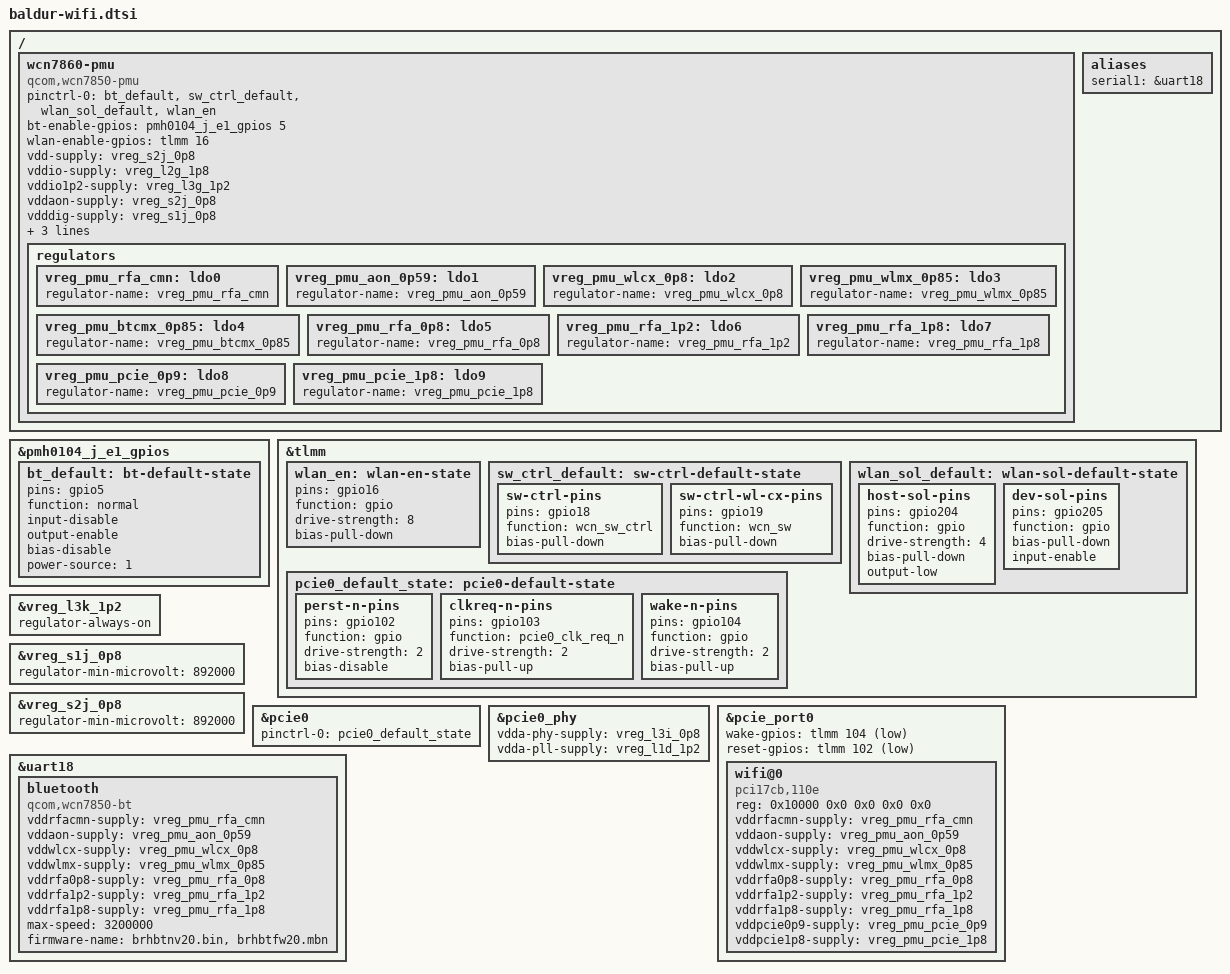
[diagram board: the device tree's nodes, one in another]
// SPDX-License-Identifier: BSD-3-Clause
/*
 * TB323FU ("baldur"): Wi-Fi, WCN7860 "peach" (17cb:110e) on PCIe0, ath12k.
 *
 * Pins as on the OnePlus 15 port and kaanapali-mtp.dts: wlan-en gpio16,
 * sw-ctrl gpio18, PERST gpio102, CLKREQ gpio103, WAKE gpio104. The rails are
 * this device's own, from its vendor cnss-peach node: AON 0.9 V comes from
 * S2J here, not from S7G as on the MTP.
 *
 * BT_EN is described so that the sequencer drives it low before it powers
 * WLAN, as the vendor cnss does: a PMIC GPIO keeps its level across a warm
 * reboot. Needs pmh0104-kaanapali.dtsi.
 */

&pmh0104_j_e1_gpios {
	bt_default: bt-default-state {
		pins = "gpio5";
		function = "normal";
		input-disable;
		output-enable;
		bias-disable;
		power-source = <1>;
	};
};

&tlmm {
	wlan_en: wlan-en-state {
		pins = "gpio16";
		function = "gpio";
		drive-strength = <8>;
		bias-pull-down;
	};

	/* vendor cnss_wlan_sw_ctrl / cnss_wlan_sw_ctrl_wl_cx */
	sw_ctrl_default: sw-ctrl-default-state {
		sw-ctrl-pins {
			pins = "gpio18";
			function = "wcn_sw_ctrl";
			bias-pull-down;
		};

		sw-ctrl-wl-cx-pins {
			pins = "gpio19";
			function = "wcn_sw";
			bias-pull-down;
		};
	};

	/*
	 * Sign-of-life lines (vendor wlan-host-sol-gpio 204, wlan-dev-sol-gpio
	 * 205): eGPIOs that another subsystem owns until something selects
	 * function "gpio". Host-SOL goes low before the chip is powered.
	 */
	wlan_sol_default: wlan-sol-default-state {
		host-sol-pins {
			pins = "gpio204";
			function = "gpio";
			drive-strength = <4>;
			bias-pull-down;
			output-low;
		};

		dev-sol-pins {
			pins = "gpio205";
			function = "gpio";
			bias-pull-down;
			input-enable;
		};
	};

	pcie0_default_state: pcie0-default-state {
		perst-n-pins {
			pins = "gpio102";
			function = "gpio";
			drive-strength = <2>;
			bias-disable;
		};

		clkreq-n-pins {
			pins = "gpio103";
			function = "pcie0_clk_req_n";
			drive-strength = <2>;
			bias-pull-up;
		};

		wake-n-pins {
			pins = "gpio104";
			function = "gpio";
			drive-strength = <2>;
			bias-pull-up;
		};
	};
};

/ {
	wcn7860-pmu {
		/* no WCN7860 binding; the WCN7850 sequencer is what the OnePlus port uses */
		compatible = "qcom,wcn7850-pmu";

		pinctrl-0 = <&bt_default>, <&sw_ctrl_default>, <&wlan_sol_default>, <&wlan_en>;
		pinctrl-names = "default";

		bt-enable-gpios = <&pmh0104_j_e1_gpios 5 GPIO_ACTIVE_HIGH>;
		wlan-enable-gpios = <&tlmm 16 GPIO_ACTIVE_HIGH>;

		vdd-supply = <&vreg_s2j_0p8>;
		vddio-supply = <&vreg_l2g_1p8>;
		vddio1p2-supply = <&vreg_l3g_1p2>;
		vddaon-supply = <&vreg_s2j_0p8>;
		vdddig-supply = <&vreg_s1j_0p8>;
		vddrfa1p2-supply = <&vreg_s7f_1p2>;
		vddrfa1p8-supply = <&vreg_s8f_1p8>;

		clocks = <&rpmhcc RPMH_RF_CLK1>;

		regulators {
			vreg_pmu_rfa_cmn: ldo0 {
				regulator-name = "vreg_pmu_rfa_cmn";
			};

			vreg_pmu_aon_0p59: ldo1 {
				regulator-name = "vreg_pmu_aon_0p59";
			};

			vreg_pmu_wlcx_0p8: ldo2 {
				regulator-name = "vreg_pmu_wlcx_0p8";
			};

			vreg_pmu_wlmx_0p85: ldo3 {
				regulator-name = "vreg_pmu_wlmx_0p85";
			};

			vreg_pmu_btcmx_0p85: ldo4 {
				regulator-name = "vreg_pmu_btcmx_0p85";
			};

			vreg_pmu_rfa_0p8: ldo5 {
				regulator-name = "vreg_pmu_rfa_0p8";
			};

			vreg_pmu_rfa_1p2: ldo6 {
				regulator-name = "vreg_pmu_rfa_1p2";
			};

			vreg_pmu_rfa_1p8: ldo7 {
				regulator-name = "vreg_pmu_rfa_1p8";
			};

			vreg_pmu_pcie_0p9: ldo8 {
				regulator-name = "vreg_pmu_pcie_0p9";
			};

			vreg_pmu_pcie_1p8: ldo9 {
				regulator-name = "vreg_pmu_pcie_1p8";
			};
		};
	};
};

&vreg_l3k_1p2 {
	regulator-always-on;
};

/*
 * WLCX/WLMX at the vendor cnss votes: the regulator core parks an unset rail
 * at its minimum (0.4/0.5 V), and nothing raises them through the PDC here.
 */
&vreg_s1j_0p8 {
	regulator-min-microvolt = <892000>;
};

&vreg_s2j_0p8 {
	regulator-min-microvolt = <892000>;
};

&pcie0 {
	pinctrl-0 = <&pcie0_default_state>;
	pinctrl-names = "default";

	status = "okay";
};

&pcie0_phy {
	vdda-phy-supply = <&vreg_l3i_0p8>;
	vdda-pll-supply = <&vreg_l1d_1p2>;

	status = "okay";
};

&pcie_port0 {
	wake-gpios = <&tlmm 104 GPIO_ACTIVE_LOW>;
	reset-gpios = <&tlmm 102 GPIO_ACTIVE_LOW>;

	wifi@0 {
		compatible = "pci17cb,110e";
		reg = <0x10000 0x0 0x0 0x0 0x0>;

		vddrfacmn-supply = <&vreg_pmu_rfa_cmn>;
		vddaon-supply = <&vreg_pmu_aon_0p59>;
		vddwlcx-supply = <&vreg_pmu_wlcx_0p8>;
		vddwlmx-supply = <&vreg_pmu_wlmx_0p85>;
		vddrfa0p8-supply = <&vreg_pmu_rfa_0p8>;
		vddrfa1p2-supply = <&vreg_pmu_rfa_1p2>;
		vddrfa1p8-supply = <&vreg_pmu_rfa_1p8>;
		vddpcie0p9-supply = <&vreg_pmu_pcie_0p9>;
		vddpcie1p8-supply = <&vreg_pmu_pcie_1p8>;
	};
};

/*
 * Bluetooth, the same chip over the 4-wire HS-UART (vendor
 * qupv3_se18_4uart @ 0x1994000 = uart18), as the OnePlus 15 port wires it.
 */
/ {
	aliases {
		/* the geni UART driver wants a line number */
		serial1 = &uart18;
	};
};

&uart18 {
	status = "okay";

	bluetooth {
		compatible = "qcom,wcn7850-bt";

		vddrfacmn-supply = <&vreg_pmu_rfa_cmn>;
		vddaon-supply = <&vreg_pmu_aon_0p59>;
		vddwlcx-supply = <&vreg_pmu_wlcx_0p8>;
		vddwlmx-supply = <&vreg_pmu_wlmx_0p85>;
		vddrfa0p8-supply = <&vreg_pmu_rfa_0p8>;
		vddrfa1p2-supply = <&vreg_pmu_rfa_1p2>;
		vddrfa1p8-supply = <&vreg_pmu_rfa_1p8>;

		/* the rate the OnePlus 15 port runs this chip at (peri baud command) */
		max-speed = <3200000>;

		/* NVM, then the BRAHMA ELF rampatch */
		firmware-name = "brhbtnv20.bin", "brhbtfw20.mbn";
	};
};
